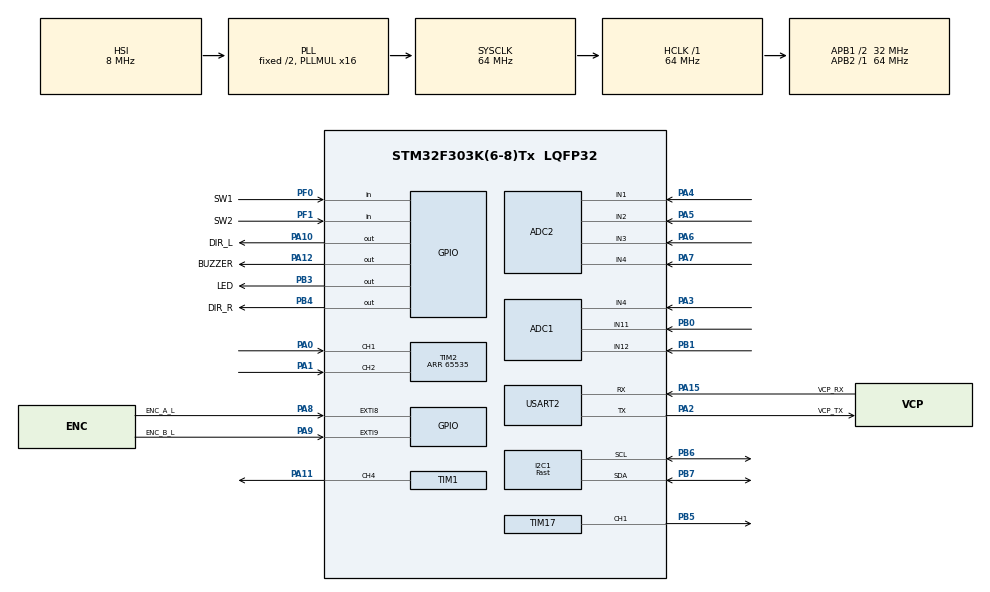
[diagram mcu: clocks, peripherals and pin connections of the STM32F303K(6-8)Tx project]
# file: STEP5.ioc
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ADC1.Channel-3\#ChannelRegularConversion=ADC_CHANNEL_4
ADC1.Channel-4\#ChannelRegularConversion=ADC_CHANNEL_11
ADC1.Channel-5\#ChannelRegularConversion=ADC_CHANNEL_12
ADC1.ContinuousConvMode=DISABLE
ADC1.DMAContinuousRequests=ENABLE
ADC1.DiscontinuousConvMode=ENABLE
ADC1.ExternalTrigConv=ADC_EXTERNALTRIGCONV_T3_TRGO
ADC1.NbrOfConversion=3
ADC1.NbrOfConversionFlag=1
ADC1.NbrOfDiscConversion=3
ADC1.Offset-3\#ChannelRegularConversion=0
ADC1.Offset-4\#ChannelRegularConversion=0
ADC1.Offset-5\#ChannelRegularConversion=0
ADC1.OffsetNumber-3\#ChannelRegularConversion=ADC_OFFSET_NONE
ADC1.OffsetNumber-4\#ChannelRegularConversion=ADC_OFFSET_NONE
ADC1.OffsetNumber-5\#ChannelRegularConversion=ADC_OFFSET_NONE
ADC1.Rank-3\#ChannelRegularConversion=1
ADC1.Rank-4\#ChannelRegularConversion=2
ADC1.Rank-5\#ChannelRegularConversion=3
ADC1.SamplingTime-3\#ChannelRegularConversion=ADC_SAMPLETIME_4CYCLES_5
ADC1.SamplingTime-4\#ChannelRegularConversion=ADC_SAMPLETIME_4CYCLES_5
ADC1.SamplingTime-5\#ChannelRegularConversion=ADC_SAMPLETIME_4CYCLES_5
ADC1.SubFamily=STM32F303x8
ADC1.master=1
ADC2.Channel-3\#ChannelRegularConversion=ADC_CHANNEL_1
ADC2.Channel-4\#ChannelRegularConversion=ADC_CHANNEL_2
ADC2.Channel-5\#ChannelRegularConversion=ADC_CHANNEL_3
ADC2.Channel-6\#ChannelRegularConversion=ADC_CHANNEL_4
ADC2.ContinuousConvMode=DISABLE
ADC2.DMAContinuousRequests=ENABLE
ADC2.DiscontinuousConvMode=ENABLE
ADC2.ExternalTrigConv=ADC_EXTERNALTRIGCONV_T3_TRGO
ADC2.NbrOfConversion=4
ADC2.NbrOfConversionFlag=1
ADC2.NbrOfDiscConversion=4
ADC2.Offset-3\#ChannelRegularConversion=0
ADC2.Offset-4\#ChannelRegularConversion=0
ADC2.Offset-5\#ChannelRegularConversion=0
ADC2.Offset-6\#ChannelRegularConversion=0
ADC2.OffsetNumber-3\#ChannelRegularConversion=ADC_OFFSET_NONE
ADC2.OffsetNumber-4\#ChannelRegularConversion=ADC_OFFSET_NONE
ADC2.OffsetNumber-5\#ChannelRegularConversion=ADC_OFFSET_NONE
ADC2.OffsetNumber-6\#ChannelRegularConversion=ADC_OFFSET_NONE
ADC2.Rank-3\#ChannelRegularConversion=1
ADC2.Rank-4\#ChannelRegularConversion=2
ADC2.Rank-5\#ChannelRegularConversion=3
ADC2.Rank-6\#ChannelRegularConversion=4
ADC2.SamplingTime-3\#ChannelRegularConversion=ADC_SAMPLETIME_4CYCLES_5
ADC2.SamplingTime-4\#ChannelRegularConversion=ADC_SAMPLETIME_4CYCLES_5
ADC2.SamplingTime-5\#ChannelRegularConversion=ADC_SAMPLETIME_4CYCLES_5
ADC2.SamplingTime-6\#ChannelRegularConversion=ADC_SAMPLETIME_4CYCLES_5
ADC2.SubFamily=STM32F303x8
Dma.ADC1.0.Direction=DMA_PERIPH_TO_MEMORY
Dma.ADC1.0.Instance=DMA1_Channel1
Dma.ADC1.0.MemDataAlignment=DMA_MDATAALIGN_HALFWORD
Dma.ADC1.0.MemInc=DMA_MINC_ENABLE
Dma.ADC1.0.Mode=DMA_CIRCULAR
Dma.ADC1.0.PeriphDataAlignment=DMA_PDATAALIGN_HALFWORD
Dma.ADC1.0.PeriphInc=DMA_PINC_DISABLE
Dma.ADC1.0.Priority=DMA_PRIORITY_LOW
Dma.ADC2.1.Direction=DMA_PERIPH_TO_MEMORY
Dma.ADC2.1.Instance=DMA1_Channel2
Dma.ADC2.1.MemDataAlignment=DMA_MDATAALIGN_HALFWORD
Dma.ADC2.1.MemInc=DMA_MINC_ENABLE
Dma.ADC2.1.Mode=DMA_CIRCULAR
Dma.ADC2.1.PeriphDataAlignment=DMA_PDATAALIGN_HALFWORD
Dma.ADC2.1.PeriphInc=DMA_PINC_DISABLE
Dma.ADC2.1.Priority=DMA_PRIORITY_LOW
Dma.I2C1_RX.2.Direction=DMA_PERIPH_TO_MEMORY
Dma.I2C1_RX.2.Instance=DMA1_Channel3
Dma.I2C1_RX.2.MemDataAlignment=DMA_MDATAALIGN_BYTE
Dma.I2C1_RX.2.MemInc=DMA_MINC_ENABLE
Dma.I2C1_RX.2.Mode=DMA_NORMAL
Dma.I2C1_RX.2.PeriphDataAlignment=DMA_PDATAALIGN_BYTE
Dma.I2C1_RX.2.PeriphInc=DMA_PINC_DISABLE
Dma.I2C1_RX.2.Priority=DMA_PRIORITY_LOW
Dma.I2C1_TX.3.Direction=DMA_MEMORY_TO_PERIPH
Dma.I2C1_TX.3.Instance=DMA1_Channel4
Dma.I2C1_TX.3.MemDataAlignment=DMA_MDATAALIGN_BYTE
Dma.I2C1_TX.3.MemInc=DMA_MINC_ENABLE
Dma.I2C1_TX.3.Mode=DMA_NORMAL
Dma.I2C1_TX.3.PeriphDataAlignment=DMA_PDATAALIGN_BYTE
Dma.I2C1_TX.3.PeriphInc=DMA_PINC_DISABLE
Dma.I2C1_TX.3.Priority=DMA_PRIORITY_LOW
Dma.Request0=ADC1
Dma.Request1=ADC2
Dma.Request2=I2C1_RX
Dma.Request3=I2C1_TX
I2C1.Analog_Filter=I2C_ANALOGFILTER_ENABLE
I2C1.I2C_Speed_Mode=I2C_Fast
I2C1.Speed=400
I2C1.Timing=0x0000020B
Mcu.Family=STM32F3
Mcu.Name=STM32F303K(6-8)Tx
Mcu.Package=LQFP32
NVIC.DMA1_Channel1_IRQn=true\:0\:0\:false\:false\:true\:false\:true
NVIC.DMA1_Channel2_IRQn=true\:0\:0\:false\:false\:true\:false\:true
NVIC.DMA1_Channel3_IRQn=true\:0\:0\:false\:false\:true\:false\:true
NVIC.DMA1_Channel4_IRQn=true\:0\:0\:false\:false\:true\:false\:true
NVIC.EXTI9_5_IRQn=true\:0\:0\:false\:false\:true\:true\:true
NVIC.I2C1_EV_IRQn=true\:0\:0\:false\:false\:true\:true\:true
NVIC.PriorityGroup=NVIC_PRIORITYGROUP_4
NVIC.TIM6_DAC1_IRQn=true\:0\:0\:false\:false\:true\:true\:true
NVIC.TIM7_DAC2_IRQn=true\:0\:0\:false\:false\:true\:true\:true
PA0.Signal=S_TIM2_CH1_ETR
PA1.Signal=S_TIM2_CH2
PA10.GPIO_Label=DIR_L
PA10.Signal=GPIO_Output
PA11.Signal=S_TIM1_CH4
PA12.GPIO_Label=BUZZER
PA12.Signal=GPIO_Output
PA13.GPIO_Label=SWDIO
PA13.Mode=Serial_Wire
PA13.Signal=SYS_JTMS-SWDIO
PA14.GPIO_Label=SWCLK
PA14.Mode=Serial_Wire
PA14.Signal=SYS_JTCK-SWCLK
PA15.GPIO_Label=VCP_RX
PA15.Mode=Asynchronous
PA15.Signal=USART2_RX
PA2.GPIO_Label=VCP_TX
PA2.Mode=Asynchronous
PA2.Signal=USART2_TX
PA3.Mode=IN4-Single-Ended
PA3.Signal=ADC1_IN4
PA4.Mode=IN1-Single-Ended
PA4.Signal=ADC2_IN1
PA5.Mode=IN2-Single-Ended
PA5.Signal=ADC2_IN2
PA6.Mode=IN3-Single-Ended
PA6.Signal=ADC2_IN3
PA7.Mode=IN4-Single-Ended
PA7.Signal=ADC2_IN4
PA8.GPIO_Label=ENC_A_L
PA8.GPIO_ModeDefaultEXTI=GPIO_MODE_IT_RISING_FALLING
PA8.Signal=GPXTI8
PA9.GPIO_Label=ENC_B_L
PA9.GPIO_ModeDefaultEXTI=GPIO_MODE_IT_RISING_FALLING
PA9.Signal=GPXTI9
PB0.Mode=IN11-Single-Ended
PB0.Signal=ADC1_IN11
PB1.Mode=IN12-Single-Ended
PB1.Signal=ADC1_IN12
PB3.GPIO_Label=LED
PB3.Signal=GPIO_Output
PB4.GPIO_Label=DIR_R
PB4.Signal=GPIO_Output
PB5.Signal=S_TIM17_CH1
PB6.GPIO_PuPdOD=GPIO_PULLUP
PB6.Mode=I2C
PB6.Signal=I2C1_SCL
PB7.GPIO_PuPdOD=GPIO_PULLUP
PB7.Mode=I2C
PB7.Signal=I2C1_SDA
PF0\ /\ OSC_IN.GPIO_Label=SW1
PF0\ /\ OSC_IN.GPIO_PuPd=GPIO_PULLUP
PF0\ /\ OSC_IN.Signal=GPIO_Input
PF1\ /\ OSC_OUT.GPIO_Label=SW2
PF1\ /\ OSC_OUT.GPIO_PuPd=GPIO_PULLUP
PF1\ /\ OSC_OUT.Signal=GPIO_Input
ProjectManager.HeapSize=0x200
ProjectManager.StackSize=0x400
ProjectManager.TargetToolchain=STM32CubeIDE
RCC.AHBFreq_Value=64000000
RCC.APB1CLKDivider=RCC_HCLK_DIV2
RCC.APB1Freq_Value=32000000
RCC.APB1TimFreq_Value=64000000
RCC.APB2Freq_Value=64000000
RCC.APB2TimFreq_Value=64000000
RCC.CortexFreq_Value=64000000
RCC.HCLKFreq_Value=64000000
RCC.HSE_VALUE=8000000
RCC.HSI_VALUE=8000000
RCC.PLLMUL=RCC_PLL_MUL16
RCC.SYSCLKFreq_VALUE=64000000
RCC.SYSCLKSourceVirtual=RCC_SYSCLKSOURCE_PLLCLK
SH.S_TIM17_CH1.0=TIM17_CH1,PWM Generation1 CH1
SH.S_TIM1_CH4.0=TIM1_CH4,PWM Generation4 CH4
SH.S_TIM2_CH1_ETR.0=TIM2_CH1,Encoder_Interface
SH.S_TIM2_CH2.0=TIM2_CH2,Encoder_Interface
TIM1.AutoReloadPreload=TIM_AUTORELOAD_PRELOAD_ENABLE
TIM1.Channel-PWM\ Generation4\ CH4=TIM_CHANNEL_4
TIM1.Period=3199
TIM1.Prescaler=0
TIM1.Pulse-PWM\ Generation4\ CH4=599
TIM17.AutoReloadPreload=TIM_AUTORELOAD_PRELOAD_ENABLE
TIM17.Channel=TIM_CHANNEL_1
TIM17.Period=3199
TIM17.Prescaler=0
TIM17.Pulse=599
TIM2.AutoReloadPreload=TIM_AUTORELOAD_PRELOAD_ENABLE
TIM2.EncoderMode=TIM_ENCODERMODE_TI12
TIM2.Period=65535
TIM3.AutoReloadPreload=TIM_AUTORELOAD_PRELOAD_ENABLE
TIM3.Period=999
TIM3.Prescaler=63
TIM3.TIM_MasterOutputTrigger=TIM_TRGO_UPDATE
TIM6.AutoReloadPreload=TIM_AUTORELOAD_PRELOAD_ENABLE
TIM6.Period=499
TIM6.Prescaler=63
TIM7.AutoReloadPreload=TIM_AUTORELOAD_PRELOAD_ENABLE
TIM7.Period=9999
TIM7.Prescaler=63
USART2.VirtualMode-Asynchronous=VM_ASYNC
VP_TIM17_VS_ClockSourceINT.Mode=Enable_Timer
VP_TIM3_VS_ClockSourceINT.Mode=Internal
VP_TIM6_VS_ClockSourceINT.Mode=Enable_Timer
VP_TIM7_VS_ClockSourceINT.Mode=Enable_Timer
board=NUCLEO-F303K8

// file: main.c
/* USER CODE BEGIN Header */
/**
  ******************************************************************************
  * @file           : main.c
  * @brief          : Main program body
  ******************************************************************************
  * @attention
  *
  * Copyright (c) 2020 RT Corporation
  * License: Apache License, Version 2.0
  * https://www.apache.org/licenses/LICENSE-2.0
  *
  * This file is licensed the Apache License, Version 2.0.
  * This file is based on the auto generated template .c file
  * released by STMicroelectronics licensed under the BSD 3-Clause License.
  *
  *=*=*=*=*=*=*=*=*=*=*=*=*=*=*=*=*=*=*=*=*=*=*=*=*=*=*=*=*=*=*=*=*=*=*=*=*=*=
  * <h2><center>&copy; Copyright (c) 2020 STMicroelectronics.
  * All rights reserved.</center></h2>
  *
  * This software component is licensed by ST under BSD 3-Clause license,
  * the "License"; You may not use this file except in compliance with the
  * License. You may obtain a copy of the License at:
  *                        opensource.org/licenses/BSD-3-Clause
  *=*=*=*=*=*=*=*=*=*=*=*=*=*=*=*=*=*=*=*=*=*=*=*=*=*=*=*=*=*=*=*=*=*=*=*=*=*=
  *
  ******************************************************************************
  */
/* USER CODE END Header */

#include "main.h"

/* USER CODE BEGIN Includes */
#include "stdio.h"
/* USER CODE END Includes */

ADC_HandleTypeDef hadc1;
ADC_HandleTypeDef hadc2;
DMA_HandleTypeDef hdma_adc1;
DMA_HandleTypeDef hdma_adc2;

I2C_HandleTypeDef hi2c1;
DMA_HandleTypeDef hdma_i2c1_rx;
DMA_HandleTypeDef hdma_i2c1_tx;

TIM_HandleTypeDef htim1;
TIM_HandleTypeDef htim2;
TIM_HandleTypeDef htim3;
TIM_HandleTypeDef htim6;
TIM_HandleTypeDef htim7;
TIM_HandleTypeDef htim17;

UART_HandleTypeDef huart2;

void SystemClock_Config(void);
static void MX_GPIO_Init(void);
static void MX_DMA_Init(void);
static void MX_USART2_UART_Init(void);
static void MX_I2C1_Init(void);
static void MX_TIM1_Init(void);
static void MX_TIM2_Init(void);
static void MX_TIM17_Init(void);
static void MX_ADC1_Init(void);
static void MX_ADC2_Init(void);
static void MX_TIM3_Init(void);
static void MX_TIM6_Init(void);
static void MX_TIM7_Init(void);
/* USER CODE BEGIN PFP */
short ADC1_DATA[10];
short ADC2_DATA[10];
/* USER CODE END PFP */

/* USER CODE BEGIN 0 */
int __io_putchar(int ch){
	HAL_UART_Transmit(&huart2, (uint8_t *)&ch, 1, 0xFFFF);
	  return ch;
}
/* USER CODE END 0 */

int main(void)
{

  /* MCU Configuration--------------------------------------------------------*/

  /* Reset of all peripherals, Initializes the Flash interface and the Systick. */
  HAL_Init();

  /* Configure the system clock */
  SystemClock_Config();

  /* Initialize all configured peripherals */
  MX_GPIO_Init();
  MX_DMA_Init();
  MX_USART2_UART_Init();
  MX_I2C1_Init();
  MX_TIM1_Init();
  MX_TIM2_Init();
  MX_TIM17_Init();
  MX_ADC1_Init();
  MX_ADC2_Init();
  MX_TIM3_Init();
  MX_TIM6_Init();
  MX_TIM7_Init();
  /* USER CODE BEGIN 2 */
  //ADC開始
    HAL_ADC_Start_DMA(&hadc1,(uint32_t *)ADC1_DATA,3);
    HAL_ADC_Start_DMA(&hadc2,(uint32_t *)ADC2_DATA,4);
    HAL_TIM_Base_Start(&htim3);//1kHz
  /* USER CODE END 2 */

  /* Infinite loop */
  /* USER CODE BEGIN WHILE */
  while (1)
  {
	  printf("\n\r LL2=%d LL1=%d LR1=%d LR2=%d",ADC2_DATA[2],ADC2_DATA[1],ADC2_DATA[0],ADC1_DATA[0]);
	  HAL_GPIO_WritePin(LED_GPIO_Port,LED_Pin,1);
	  HAL_Delay(100);
	  HAL_GPIO_WritePin(LED_GPIO_Port,LED_Pin,0);
	  HAL_Delay(100);
    /* USER CODE END WHILE */
  }
}

void SystemClock_Config(void)
{
  RCC_OscInitTypeDef RCC_OscInitStruct = {0};
  RCC_ClkInitTypeDef RCC_ClkInitStruct = {0};
  RCC_PeriphCLKInitTypeDef PeriphClkInit = {0};

  /** Initializes the CPU, AHB and APB busses clocks
  */
  RCC_OscInitStruct.OscillatorType = RCC_OSCILLATORTYPE_HSI;
  RCC_OscInitStruct.HSIState = RCC_HSI_ON;
  RCC_OscInitStruct.HSICalibrationValue = RCC_HSICALIBRATION_DEFAULT;
  RCC_OscInitStruct.PLL.PLLState = RCC_PLL_ON;
  RCC_OscInitStruct.PLL.PLLSource = RCC_PLLSOURCE_HSI;
  RCC_OscInitStruct.PLL.PLLMUL = RCC_PLL_MUL16;
  if (HAL_RCC_OscConfig(&RCC_OscInitStruct) != HAL_OK)
  {
    Error_Handler();
  }
  /** Initializes the CPU, AHB and APB busses clocks
  */
  RCC_ClkInitStruct.ClockType = RCC_CLOCKTYPE_HCLK|RCC_CLOCKTYPE_SYSCLK
                              |RCC_CLOCKTYPE_PCLK1|RCC_CLOCKTYPE_PCLK2;
  RCC_ClkInitStruct.SYSCLKSource = RCC_SYSCLKSOURCE_PLLCLK;
  RCC_ClkInitStruct.AHBCLKDivider = RCC_SYSCLK_DIV1;
  RCC_ClkInitStruct.APB1CLKDivider = RCC_HCLK_DIV2;
  RCC_ClkInitStruct.APB2CLKDivider = RCC_HCLK_DIV1;

  if (HAL_RCC_ClockConfig(&RCC_ClkInitStruct, FLASH_LATENCY_2) != HAL_OK)
  {
    Error_Handler();
  }
  PeriphClkInit.PeriphClockSelection = RCC_PERIPHCLK_I2C1|RCC_PERIPHCLK_TIM1
                              |RCC_PERIPHCLK_ADC12;
  PeriphClkInit.Adc12ClockSelection = RCC_ADC12PLLCLK_DIV1;
  PeriphClkInit.I2c1ClockSelection = RCC_I2C1CLKSOURCE_HSI;
  PeriphClkInit.Tim1ClockSelection = RCC_TIM1CLK_HCLK;
  if (HAL_RCCEx_PeriphCLKConfig(&PeriphClkInit) != HAL_OK)
  {
    Error_Handler();
  }
}

static void MX_ADC1_Init(void)
{

  ADC_MultiModeTypeDef multimode = {0};
  ADC_ChannelConfTypeDef sConfig = {0};

  /** Common config
  */
  hadc1.Instance = ADC1;
  hadc1.Init.ClockPrescaler = ADC_CLOCK_ASYNC_DIV1;
  hadc1.Init.Resolution = ADC_RESOLUTION_12B;
  hadc1.Init.ScanConvMode = ADC_SCAN_ENABLE;
  hadc1.Init.ContinuousConvMode = DISABLE;
  hadc1.Init.DiscontinuousConvMode = ENABLE;
  hadc1.Init.NbrOfDiscConversion = 3;
  hadc1.Init.ExternalTrigConvEdge = ADC_EXTERNALTRIGCONVEDGE_RISING;
  hadc1.Init.ExternalTrigConv = ADC_EXTERNALTRIGCONV_T3_TRGO;
  hadc1.Init.DataAlign = ADC_DATAALIGN_RIGHT;
  hadc1.Init.NbrOfConversion = 3;
  hadc1.Init.DMAContinuousRequests = ENABLE;
  hadc1.Init.EOCSelection = ADC_EOC_SINGLE_CONV;
  hadc1.Init.LowPowerAutoWait = DISABLE;
  hadc1.Init.Overrun = ADC_OVR_DATA_OVERWRITTEN;
  if (HAL_ADC_Init(&hadc1) != HAL_OK)
  {
    Error_Handler();
  }
  /** Configure the ADC multi-mode
  */
  multimode.Mode = ADC_MODE_INDEPENDENT;
  if (HAL_ADCEx_MultiModeConfigChannel(&hadc1, &multimode) != HAL_OK)
  {
    Error_Handler();
  }
  /** Configure Regular Channel
  */
  sConfig.Channel = ADC_CHANNEL_4;
  sConfig.Rank = ADC_REGULAR_RANK_1;
  sConfig.SingleDiff = ADC_SINGLE_ENDED;
  sConfig.SamplingTime = ADC_SAMPLETIME_4CYCLES_5;
  sConfig.OffsetNumber = ADC_OFFSET_NONE;
  sConfig.Offset = 0;
  if (HAL_ADC_ConfigChannel(&hadc1, &sConfig) != HAL_OK)
  {
    Error_Handler();
  }
  /** Configure Regular Channel
  */
  sConfig.Channel = ADC_CHANNEL_11;
  sConfig.Rank = ADC_REGULAR_RANK_2;
  if (HAL_ADC_ConfigChannel(&hadc1, &sConfig) != HAL_OK)
  {
    Error_Handler();
  }
  /** Configure Regular Channel
  */
  sConfig.Channel = ADC_CHANNEL_12;
  sConfig.Rank = ADC_REGULAR_RANK_3;
  if (HAL_ADC_ConfigChannel(&hadc1, &sConfig) != HAL_OK)
  {
    Error_Handler();
  }

}

static void MX_ADC2_Init(void)
{

  ADC_ChannelConfTypeDef sConfig = {0};

  /** Common config
  */
  hadc2.Instance = ADC2;
  hadc2.Init.ClockPrescaler = ADC_CLOCK_ASYNC_DIV1;
  hadc2.Init.Resolution = ADC_RESOLUTION_12B;
  hadc2.Init.ScanConvMode = ADC_SCAN_ENABLE;
  hadc2.Init.ContinuousConvMode = DISABLE;
  hadc2.Init.DiscontinuousConvMode = ENABLE;
  hadc2.Init.NbrOfDiscConversion = 4;
  hadc2.Init.ExternalTrigConvEdge = ADC_EXTERNALTRIGCONVEDGE_RISING;
  hadc2.Init.ExternalTrigConv = ADC_EXTERNALTRIGCONV_T3_TRGO;
  hadc2.Init.DataAlign = ADC_DATAALIGN_RIGHT;
  hadc2.Init.NbrOfConversion = 4;
  hadc2.Init.DMAContinuousRequests = ENABLE;
  hadc2.Init.EOCSelection = ADC_EOC_SINGLE_CONV;
  hadc2.Init.LowPowerAutoWait = DISABLE;
  hadc2.Init.Overrun = ADC_OVR_DATA_OVERWRITTEN;
  if (HAL_ADC_Init(&hadc2) != HAL_OK)
  {
    Error_Handler();
  }
  /** Configure Regular Channel
  */
  sConfig.Channel = ADC_CHANNEL_1;
  sConfig.Rank = ADC_REGULAR_RANK_1;
  sConfig.SingleDiff = ADC_SINGLE_ENDED;
  sConfig.SamplingTime = ADC_SAMPLETIME_4CYCLES_5;
  sConfig.OffsetNumber = ADC_OFFSET_NONE;
  sConfig.Offset = 0;
  if (HAL_ADC_ConfigChannel(&hadc2, &sConfig) != HAL_OK)
  {
    Error_Handler();
  }
  /** Configure Regular Channel
  */
  sConfig.Channel = ADC_CHANNEL_2;
  sConfig.Rank = ADC_REGULAR_RANK_2;
  if (HAL_ADC_ConfigChannel(&hadc2, &sConfig) != HAL_OK)
  {
    Error_Handler();
  }
  /** Configure Regular Channel
  */
  sConfig.Channel = ADC_CHANNEL_3;
  sConfig.Rank = ADC_REGULAR_RANK_3;
  if (HAL_ADC_ConfigChannel(&hadc2, &sConfig) != HAL_OK)
  {
    Error_Handler();
  }
  /** Configure Regular Channel
  */
  sConfig.Channel = ADC_CHANNEL_4;
  sConfig.Rank = ADC_REGULAR_RANK_4;
  if (HAL_ADC_ConfigChannel(&hadc2, &sConfig) != HAL_OK)
  {
    Error_Handler();
  }

}

static void MX_I2C1_Init(void)
{

  hi2c1.Instance = I2C1;
  hi2c1.Init.Timing = 0x0000020B;
  hi2c1.Init.OwnAddress1 = 0;
  hi2c1.Init.AddressingMode = I2C_ADDRESSINGMODE_7BIT;
  hi2c1.Init.DualAddressMode = I2C_DUALADDRESS_DISABLE;
  hi2c1.Init.OwnAddress2 = 0;
  hi2c1.Init.OwnAddress2Masks = I2C_OA2_NOMASK;
  hi2c1.Init.GeneralCallMode = I2C_GENERALCALL_DISABLE;
  hi2c1.Init.NoStretchMode = I2C_NOSTRETCH_DISABLE;
  if (HAL_I2C_Init(&hi2c1) != HAL_OK)
  {
    Error_Handler();
  }
  /** Configure Analogue filter
  */
  if (HAL_I2CEx_ConfigAnalogFilter(&hi2c1, I2C_ANALOGFILTER_ENABLE) != HAL_OK)
  {
    Error_Handler();
  }
  /** Configure Digital filter
  */
  if (HAL_I2CEx_ConfigDigitalFilter(&hi2c1, 0) != HAL_OK)
  {
    Error_Handler();
  }

}

static void MX_TIM1_Init(void)
{

  TIM_MasterConfigTypeDef sMasterConfig = {0};
  TIM_OC_InitTypeDef sConfigOC = {0};
  TIM_BreakDeadTimeConfigTypeDef sBreakDeadTimeConfig = {0};

  htim1.Instance = TIM1;
  htim1.Init.Prescaler = 0;
  htim1.Init.CounterMode = TIM_COUNTERMODE_UP;
  htim1.Init.Period = 3199;
  htim1.Init.ClockDivision = TIM_CLOCKDIVISION_DIV1;
  htim1.Init.RepetitionCounter = 0;
  htim1.Init.AutoReloadPreload = TIM_AUTORELOAD_PRELOAD_ENABLE;
  if (HAL_TIM_PWM_Init(&htim1) != HAL_OK)
  {
    Error_Handler();
  }
  sMasterConfig.MasterOutputTrigger = TIM_TRGO_RESET;
  sMasterConfig.MasterOutputTrigger2 = TIM_TRGO2_RESET;
  sMasterConfig.MasterSlaveMode = TIM_MASTERSLAVEMODE_DISABLE;
  if (HAL_TIMEx_MasterConfigSynchronization(&htim1, &sMasterConfig) != HAL_OK)
  {
    Error_Handler();
  }
  sConfigOC.OCMode = TIM_OCMODE_PWM1;
  sConfigOC.Pulse = 599;
  sConfigOC.OCPolarity = TIM_OCPOLARITY_HIGH;
  sConfigOC.OCFastMode = TIM_OCFAST_DISABLE;
  sConfigOC.OCIdleState = TIM_OCIDLESTATE_RESET;
  sConfigOC.OCNIdleState = TIM_OCNIDLESTATE_RESET;
  if (HAL_TIM_PWM_ConfigChannel(&htim1, &sConfigOC, TIM_CHANNEL_4) != HAL_OK)
  {
    Error_Handler();
  }
  sBreakDeadTimeConfig.OffStateRunMode = TIM_OSSR_DISABLE;
  sBreakDeadTimeConfig.OffStateIDLEMode = TIM_OSSI_DISABLE;
  sBreakDeadTimeConfig.LockLevel = TIM_LOCKLEVEL_OFF;
  sBreakDeadTimeConfig.DeadTime = 0;
  sBreakDeadTimeConfig.BreakState = TIM_BREAK_DISABLE;
  sBreakDeadTimeConfig.BreakPolarity = TIM_BREAKPOLARITY_HIGH;
  sBreakDeadTimeConfig.BreakFilter = 0;
  sBreakDeadTimeConfig.Break2State = TIM_BREAK2_DISABLE;
  sBreakDeadTimeConfig.Break2Polarity = TIM_BREAK2POLARITY_HIGH;
  sBreakDeadTimeConfig.Break2Filter = 0;
  sBreakDeadTimeConfig.AutomaticOutput = TIM_AUTOMATICOUTPUT_DISABLE;
  if (HAL_TIMEx_ConfigBreakDeadTime(&htim1, &sBreakDeadTimeConfig) != HAL_OK)
  {
    Error_Handler();
  }
  HAL_TIM_MspPostInit(&htim1);

}

static void MX_TIM2_Init(void)
{

  TIM_Encoder_InitTypeDef sConfig = {0};
  TIM_MasterConfigTypeDef sMasterConfig = {0};

  htim2.Instance = TIM2;
  htim2.Init.Prescaler = 0;
  htim2.Init.CounterMode = TIM_COUNTERMODE_UP;
  htim2.Init.Period = 65535;
  htim2.Init.ClockDivision = TIM_CLOCKDIVISION_DIV1;
  htim2.Init.AutoReloadPreload = TIM_AUTORELOAD_PRELOAD_ENABLE;
  sConfig.EncoderMode = TIM_ENCODERMODE_TI12;
  sConfig.IC1Polarity = TIM_ICPOLARITY_RISING;
  sConfig.IC1Selection = TIM_ICSELECTION_DIRECTTI;
  sConfig.IC1Prescaler = TIM_ICPSC_DIV1;
  sConfig.IC1Filter = 0;
  sConfig.IC2Polarity = TIM_ICPOLARITY_RISING;
  sConfig.IC2Selection = TIM_ICSELECTION_DIRECTTI;
  sConfig.IC2Prescaler = TIM_ICPSC_DIV1;
  sConfig.IC2Filter = 0;
  if (HAL_TIM_Encoder_Init(&htim2, &sConfig) != HAL_OK)
  {
    Error_Handler();
  }
  sMasterConfig.MasterOutputTrigger = TIM_TRGO_RESET;
  sMasterConfig.MasterSlaveMode = TIM_MASTERSLAVEMODE_DISABLE;
  if (HAL_TIMEx_MasterConfigSynchronization(&htim2, &sMasterConfig) != HAL_OK)
  {
    Error_Handler();
  }

}

static void MX_TIM3_Init(void)
{

  TIM_ClockConfigTypeDef sClockSourceConfig = {0};
  TIM_MasterConfigTypeDef sMasterConfig = {0};

  htim3.Instance = TIM3;
  htim3.Init.Prescaler = 63;
  htim3.Init.CounterMode = TIM_COUNTERMODE_UP;
  htim3.Init.Period = 999;
  htim3.Init.ClockDivision = TIM_CLOCKDIVISION_DIV1;
  htim3.Init.AutoReloadPreload = TIM_AUTORELOAD_PRELOAD_ENABLE;
  if (HAL_TIM_Base_Init(&htim3) != HAL_OK)
  {
    Error_Handler();
  }
  sClockSourceConfig.ClockSource = TIM_CLOCKSOURCE_INTERNAL;
  if (HAL_TIM_ConfigClockSource(&htim3, &sClockSourceConfig) != HAL_OK)
  {
    Error_Handler();
  }
  sMasterConfig.MasterOutputTrigger = TIM_TRGO_UPDATE;
  sMasterConfig.MasterSlaveMode = TIM_MASTERSLAVEMODE_DISABLE;
  if (HAL_TIMEx_MasterConfigSynchronization(&htim3, &sMasterConfig) != HAL_OK)
  {
    Error_Handler();
  }

}

static void MX_TIM6_Init(void)
{

  TIM_MasterConfigTypeDef sMasterConfig = {0};

  htim6.Instance = TIM6;
  htim6.Init.Prescaler = 63;
  htim6.Init.CounterMode = TIM_COUNTERMODE_UP;
  htim6.Init.Period = 499;
  htim6.Init.AutoReloadPreload = TIM_AUTORELOAD_PRELOAD_ENABLE;
  if (HAL_TIM_Base_Init(&htim6) != HAL_OK)
  {
    Error_Handler();
  }
  sMasterConfig.MasterOutputTrigger = TIM_TRGO_RESET;
  sMasterConfig.MasterSlaveMode = TIM_MASTERSLAVEMODE_DISABLE;
  if (HAL_TIMEx_MasterConfigSynchronization(&htim6, &sMasterConfig) != HAL_OK)
  {
    Error_Handler();
  }

}

static void MX_TIM7_Init(void)
{

  TIM_MasterConfigTypeDef sMasterConfig = {0};

  htim7.Instance = TIM7;
  htim7.Init.Prescaler = 63;
  htim7.Init.CounterMode = TIM_COUNTERMODE_UP;
  htim7.Init.Period = 9999;
  htim7.Init.AutoReloadPreload = TIM_AUTORELOAD_PRELOAD_ENABLE;
  if (HAL_TIM_Base_Init(&htim7) != HAL_OK)
  {
    Error_Handler();
  }
  sMasterConfig.MasterOutputTrigger = TIM_TRGO_RESET;
  sMasterConfig.MasterSlaveMode = TIM_MASTERSLAVEMODE_DISABLE;
  if (HAL_TIMEx_MasterConfigSynchronization(&htim7, &sMasterConfig) != HAL_OK)
  {
    Error_Handler();
  }

}

static void MX_TIM17_Init(void)
{

  TIM_OC_InitTypeDef sConfigOC = {0};
  TIM_BreakDeadTimeConfigTypeDef sBreakDeadTimeConfig = {0};

  htim17.Instance = TIM17;
  htim17.Init.Prescaler = 0;
  htim17.Init.CounterMode = TIM_COUNTERMODE_UP;
  htim17.Init.Period = 3199;
  htim17.Init.ClockDivision = TIM_CLOCKDIVISION_DIV1;
  htim17.Init.RepetitionCounter = 0;
  htim17.Init.AutoReloadPreload = TIM_AUTORELOAD_PRELOAD_ENABLE;
  if (HAL_TIM_Base_Init(&htim17) != HAL_OK)
  {
    Error_Handler();
  }
  if (HAL_TIM_PWM_Init(&htim17) != HAL_OK)
  {
    Error_Handler();
  }
  sConfigOC.OCMode = TIM_OCMODE_PWM1;
  sConfigOC.Pulse = 599;
  sConfigOC.OCPolarity = TIM_OCPOLARITY_HIGH;
  sConfigOC.OCNPolarity = TIM_OCNPOLARITY_HIGH;
  sConfigOC.OCFastMode = TIM_OCFAST_DISABLE;
  sConfigOC.OCIdleState = TIM_OCIDLESTATE_RESET;
  sConfigOC.OCNIdleState = TIM_OCNIDLESTATE_RESET;
  if (HAL_TIM_PWM_ConfigChannel(&htim17, &sConfigOC, TIM_CHANNEL_1) != HAL_OK)
  {
    Error_Handler();
  }
  sBreakDeadTimeConfig.OffStateRunMode = TIM_OSSR_DISABLE;
  sBreakDeadTimeConfig.OffStateIDLEMode = TIM_OSSI_DISABLE;
  sBreakDeadTimeConfig.LockLevel = TIM_LOCKLEVEL_OFF;
  sBreakDeadTimeConfig.DeadTime = 0;
  sBreakDeadTimeConfig.BreakState = TIM_BREAK_DISABLE;
  sBreakDeadTimeConfig.BreakPolarity = TIM_BREAKPOLARITY_HIGH;
  sBreakDeadTimeConfig.BreakFilter = 0;
  sBreakDeadTimeConfig.AutomaticOutput = TIM_AUTOMATICOUTPUT_DISABLE;
  if (HAL_TIMEx_ConfigBreakDeadTime(&htim17, &sBreakDeadTimeConfig) != HAL_OK)
  {
    Error_Handler();
  }
  HAL_TIM_MspPostInit(&htim17);

}

static void MX_USART2_UART_Init(void)
{

  huart2.Instance = USART2;
  huart2.Init.BaudRate = 38400;
  huart2.Init.WordLength = UART_WORDLENGTH_8B;
  huart2.Init.StopBits = UART_STOPBITS_1;
  huart2.Init.Parity = UART_PARITY_NONE;
  huart2.Init.Mode = UART_MODE_TX_RX;
  huart2.Init.HwFlowCtl = UART_HWCONTROL_NONE;
  huart2.Init.OverSampling = UART_OVERSAMPLING_16;
  huart2.Init.OneBitSampling = UART_ONE_BIT_SAMPLE_DISABLE;
  huart2.AdvancedInit.AdvFeatureInit = UART_ADVFEATURE_NO_INIT;
  if (HAL_UART_Init(&huart2) != HAL_OK)
  {
    Error_Handler();
  }

}

static void MX_DMA_Init(void)
{

  /* DMA controller clock enable */
  __HAL_RCC_DMA1_CLK_ENABLE();

  /* DMA interrupt init */
  /* DMA1_Channel1_IRQn interrupt configuration */
  HAL_NVIC_SetPriority(DMA1_Channel1_IRQn, 0, 0);
  HAL_NVIC_EnableIRQ(DMA1_Channel1_IRQn);
  /* DMA1_Channel2_IRQn interrupt configuration */
  HAL_NVIC_SetPriority(DMA1_Channel2_IRQn, 0, 0);
  HAL_NVIC_EnableIRQ(DMA1_Channel2_IRQn);
  /* DMA1_Channel3_IRQn interrupt configuration */
  HAL_NVIC_SetPriority(DMA1_Channel3_IRQn, 0, 0);
  HAL_NVIC_EnableIRQ(DMA1_Channel3_IRQn);
  /* DMA1_Channel4_IRQn interrupt configuration */
  HAL_NVIC_SetPriority(DMA1_Channel4_IRQn, 0, 0);
  HAL_NVIC_EnableIRQ(DMA1_Channel4_IRQn);

}

static void MX_GPIO_Init(void)
{
  GPIO_InitTypeDef GPIO_InitStruct = {0};

  /* GPIO Ports Clock Enable */
  __HAL_RCC_GPIOF_CLK_ENABLE();
  __HAL_RCC_GPIOA_CLK_ENABLE();
  __HAL_RCC_GPIOB_CLK_ENABLE();

  /*Configure GPIO pin Output Level */
  HAL_GPIO_WritePin(GPIOA, DIR_L_Pin|BUZZER_Pin, GPIO_PIN_RESET);

  /*Configure GPIO pin Output Level */
  HAL_GPIO_WritePin(GPIOB, LED_Pin|DIR_R_Pin, GPIO_PIN_RESET);

  /*Configure GPIO pins : SW1_Pin SW2_Pin */
  GPIO_InitStruct.Pin = SW1_Pin|SW2_Pin;
  GPIO_InitStruct.Mode = GPIO_MODE_INPUT;
  GPIO_InitStruct.Pull = GPIO_PULLUP;
  HAL_GPIO_Init(GPIOF, &GPIO_InitStruct);

  /*Configure GPIO pin : ENC_A_L_Pin */
  GPIO_InitStruct.Pin = ENC_A_L_Pin;
  GPIO_InitStruct.Mode = GPIO_MODE_IT_RISING_FALLING;
  GPIO_InitStruct.Pull = GPIO_NOPULL;
  HAL_GPIO_Init(ENC_A_L_GPIO_Port, &GPIO_InitStruct);

  /*Configure GPIO pin : ENC_B_L_Pin */
  GPIO_InitStruct.Pin = ENC_B_L_Pin;
  GPIO_InitStruct.Mode = GPIO_MODE_IT_RISING;
  GPIO_InitStruct.Pull = GPIO_NOPULL;
  HAL_GPIO_Init(ENC_B_L_GPIO_Port, &GPIO_InitStruct);

  /*Configure GPIO pins : DIR_L_Pin BUZZER_Pin */
  GPIO_InitStruct.Pin = DIR_L_Pin|BUZZER_Pin;
  GPIO_InitStruct.Mode = GPIO_MODE_OUTPUT_PP;
  GPIO_InitStruct.Pull = GPIO_NOPULL;
  GPIO_InitStruct.Speed = GPIO_SPEED_FREQ_LOW;
  HAL_GPIO_Init(GPIOA, &GPIO_InitStruct);

  /*Configure GPIO pins : LED_Pin DIR_R_Pin */
  GPIO_InitStruct.Pin = LED_Pin|DIR_R_Pin;
  GPIO_InitStruct.Mode = GPIO_MODE_OUTPUT_PP;
  GPIO_InitStruct.Pull = GPIO_NOPULL;
  GPIO_InitStruct.Speed = GPIO_SPEED_FREQ_LOW;
  HAL_GPIO_Init(GPIOB, &GPIO_InitStruct);

  /* EXTI interrupt init*/
  HAL_NVIC_SetPriority(EXTI9_5_IRQn, 0, 0);
  HAL_NVIC_EnableIRQ(EXTI9_5_IRQn);

}

void Error_Handler(void)
{
}

/************************ (C) COPYRIGHT STMicroelectronics *****END OF FILE****/
